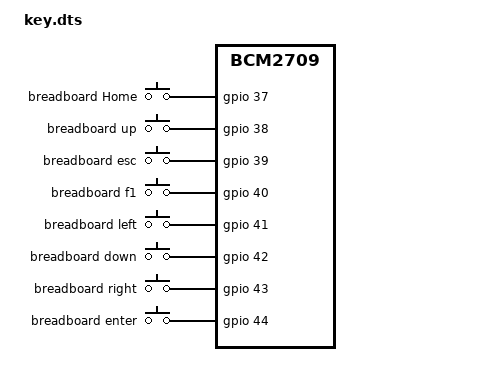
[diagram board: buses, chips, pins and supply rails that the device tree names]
/dts-v1/;
/plugin/;
/ {
   compatible = "brcm,bcm2835", "brcm,bcm2708", "brcm,bcm2709";
   
   fragment@0 {
      target-path = "/";
      __overlay__ {
         keypad: breadboard_keys {
            compatible = "gpio-keys";
            #address-cells = <1>;
            #size-cells = <0>;
	         autorepeat;
            button@37 {
               label = "breadboard Home";
               linux,code = <102>;
               gpios = <&gpio 37 0>;
            };
            button@38 {
               label = "breadboard up";
               linux,code = <103>;
               gpios = <&gpio 38 0>;
            };
            button@39 {
               label = "breadboard esc";
               linux,code = <1>;
               gpios = <&gpio 39 0>;
            };
            button@40 {
               label = "breadboard f1";
               linux,code = <59>;
               gpios = <&gpio 40 0>;
            };
            button@41 {
               label = "breadboard left";
               linux,code = <105>;
               gpios = <&gpio 41 0>;
            };
            button@42 {
               label = "breadboard down";
               linux,code = <108>;
               gpios = <&gpio 42 0>;
            };
            button@43 {
               label = "breadboard right";
               linux,code = <106>;
               gpios = <&gpio 43 0>;
            };
            button@44 {
               label = "breadboard enter";
               linux,code = <28>;
               gpios = <&gpio 44 0>;
            };
         };
      };
   };
};
